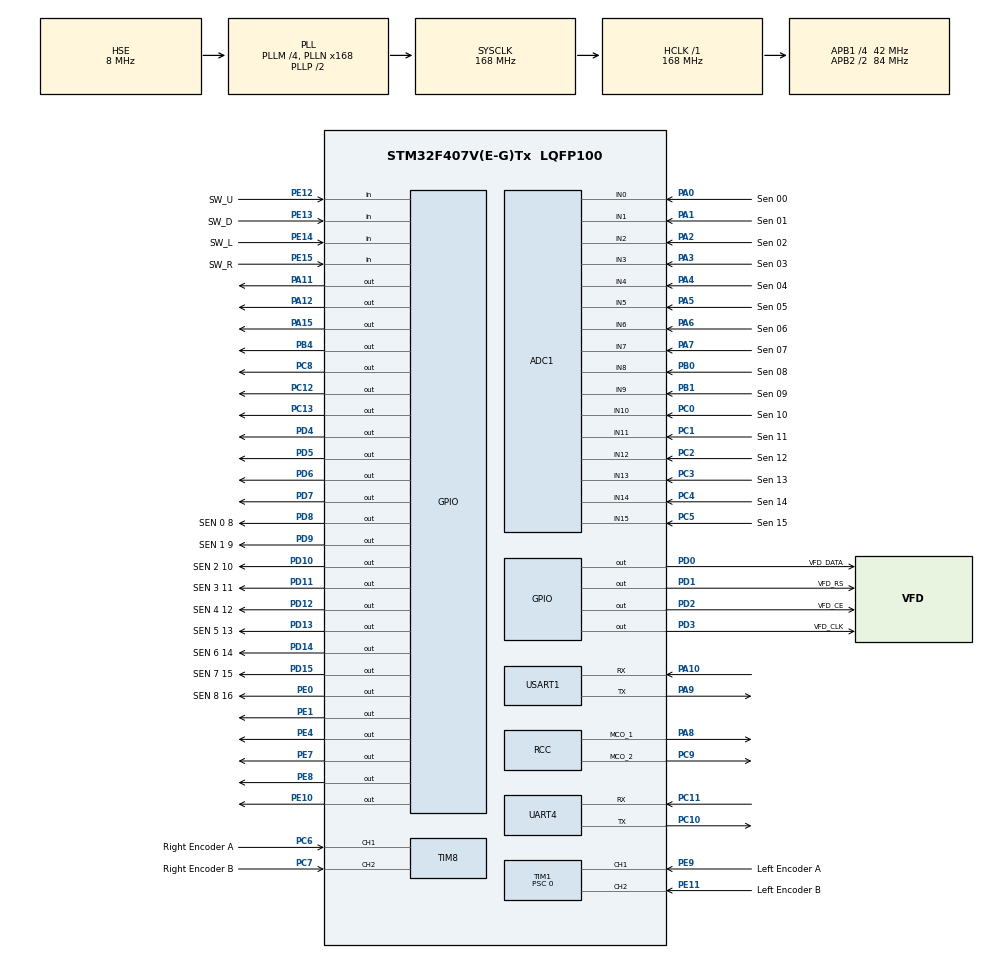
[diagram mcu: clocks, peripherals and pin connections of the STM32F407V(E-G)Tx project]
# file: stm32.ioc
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ADC1.Channel-0\#ChannelRegularConversion=ADC_CHANNEL_9
ADC1.Channel-1\#ChannelRegularConversion=ADC_CHANNEL_0
ADC1.Channel-10\#ChannelRegularConversion=ADC_CHANNEL_0
ADC1.Channel-11\#ChannelRegularConversion=ADC_CHANNEL_0
ADC1.Channel-12\#ChannelRegularConversion=ADC_CHANNEL_0
ADC1.Channel-13\#ChannelRegularConversion=ADC_CHANNEL_0
ADC1.Channel-14\#ChannelRegularConversion=ADC_CHANNEL_0
ADC1.Channel-15\#ChannelRegularConversion=ADC_CHANNEL_0
ADC1.Channel-2\#ChannelRegularConversion=ADC_CHANNEL_0
ADC1.Channel-3\#ChannelRegularConversion=ADC_CHANNEL_0
ADC1.Channel-4\#ChannelRegularConversion=ADC_CHANNEL_0
ADC1.Channel-5\#ChannelRegularConversion=ADC_CHANNEL_0
ADC1.Channel-6\#ChannelRegularConversion=ADC_CHANNEL_0
ADC1.Channel-7\#ChannelRegularConversion=ADC_CHANNEL_0
ADC1.Channel-8\#ChannelRegularConversion=ADC_CHANNEL_0
ADC1.Channel-9\#ChannelRegularConversion=ADC_CHANNEL_0
ADC1.ContinuousConvMode=ENABLE
ADC1.DMAContinuousRequests=ENABLE
ADC1.DiscontinuousConvMode=DISABLE
ADC1.EOCSelection=ADC_EOC_SEQ_CONV
ADC1.NbrOfConversion=16
ADC1.NbrOfConversionFlag=1
ADC1.Rank-0\#ChannelRegularConversion=1
ADC1.Rank-1\#ChannelRegularConversion=2
ADC1.Rank-10\#ChannelRegularConversion=11
ADC1.Rank-11\#ChannelRegularConversion=12
ADC1.Rank-12\#ChannelRegularConversion=13
ADC1.Rank-13\#ChannelRegularConversion=14
ADC1.Rank-14\#ChannelRegularConversion=15
ADC1.Rank-15\#ChannelRegularConversion=16
ADC1.Rank-2\#ChannelRegularConversion=3
ADC1.Rank-3\#ChannelRegularConversion=4
ADC1.Rank-4\#ChannelRegularConversion=5
ADC1.Rank-5\#ChannelRegularConversion=6
ADC1.Rank-6\#ChannelRegularConversion=7
ADC1.Rank-7\#ChannelRegularConversion=8
ADC1.Rank-8\#ChannelRegularConversion=9
ADC1.Rank-9\#ChannelRegularConversion=10
ADC1.SamplingTime-0\#ChannelRegularConversion=ADC_SAMPLETIME_15CYCLES
ADC1.SamplingTime-1\#ChannelRegularConversion=ADC_SAMPLETIME_15CYCLES
ADC1.SamplingTime-10\#ChannelRegularConversion=ADC_SAMPLETIME_15CYCLES
ADC1.SamplingTime-11\#ChannelRegularConversion=ADC_SAMPLETIME_15CYCLES
ADC1.SamplingTime-12\#ChannelRegularConversion=ADC_SAMPLETIME_15CYCLES
ADC1.SamplingTime-13\#ChannelRegularConversion=ADC_SAMPLETIME_15CYCLES
ADC1.SamplingTime-14\#ChannelRegularConversion=ADC_SAMPLETIME_15CYCLES
ADC1.SamplingTime-15\#ChannelRegularConversion=ADC_SAMPLETIME_15CYCLES
ADC1.SamplingTime-2\#ChannelRegularConversion=ADC_SAMPLETIME_15CYCLES
ADC1.SamplingTime-3\#ChannelRegularConversion=ADC_SAMPLETIME_15CYCLES
ADC1.SamplingTime-4\#ChannelRegularConversion=ADC_SAMPLETIME_15CYCLES
ADC1.SamplingTime-5\#ChannelRegularConversion=ADC_SAMPLETIME_15CYCLES
ADC1.SamplingTime-6\#ChannelRegularConversion=ADC_SAMPLETIME_15CYCLES
ADC1.SamplingTime-7\#ChannelRegularConversion=ADC_SAMPLETIME_15CYCLES
ADC1.SamplingTime-8\#ChannelRegularConversion=ADC_SAMPLETIME_15CYCLES
ADC1.SamplingTime-9\#ChannelRegularConversion=ADC_SAMPLETIME_15CYCLES
ADC1.master=1
Dma.ADC1.0.Direction=DMA_PERIPH_TO_MEMORY
Dma.ADC1.0.FIFOMode=DMA_FIFOMODE_DISABLE
Dma.ADC1.0.Instance=DMA2_Stream0
Dma.ADC1.0.MemDataAlignment=DMA_MDATAALIGN_WORD
Dma.ADC1.0.MemInc=DMA_MINC_ENABLE
Dma.ADC1.0.Mode=DMA_CIRCULAR
Dma.ADC1.0.PeriphDataAlignment=DMA_PDATAALIGN_WORD
Dma.ADC1.0.PeriphInc=DMA_PINC_DISABLE
Dma.ADC1.0.Priority=DMA_PRIORITY_LOW
Dma.Request0=ADC1
Mcu.Family=STM32F4
Mcu.Name=STM32F407V(E-G)Tx
Mcu.Package=LQFP100
NVIC.ADC_IRQn=true\:0\:0\:false\:false\:true\:true\:true\:true
NVIC.DMA2_Stream0_IRQn=true\:0\:0\:false\:false\:true\:false\:true\:true
NVIC.PriorityGroup=NVIC_PRIORITYGROUP_4
NVIC.TIM1_BRK_TIM9_IRQn=true\:0\:0\:false\:false\:true\:true\:true\:true
NVIC.TIM4_IRQn=true\:0\:0\:false\:false\:true\:true\:true\:true
PA0-WKUP.GPIO_Label=Sen 00
PA0-WKUP.Signal=ADCx_IN0
PA1.GPIO_Label=Sen 01
PA1.Signal=ADCx_IN1
PA10.Mode=Asynchronous
PA10.Signal=USART1_RX
PA11.Signal=GPIO_Output
PA12.Signal=GPIO_Output
PA13.Mode=Serial_Wire
PA13.Signal=SYS_JTMS-SWDIO
PA14.Mode=Serial_Wire
PA14.Signal=SYS_JTCK-SWCLK
PA15.PinState=GPIO_PIN_SET
PA15.Signal=GPIO_Output
PA2.GPIO_Label=Sen 02
PA2.Signal=ADCx_IN2
PA3.GPIO_Label=Sen 03
PA3.Signal=ADCx_IN3
PA4.GPIO_Label=Sen 04
PA4.Signal=ADCx_IN4
PA5.GPIO_Label=Sen 05
PA5.Signal=ADCx_IN5
PA6.GPIO_Label=Sen 06
PA6.Signal=ADCx_IN6
PA7.GPIO_Label=Sen 07
PA7.Signal=ADCx_IN7
PA8.Mode=Clock-out-1
PA8.Signal=RCC_MCO_1
PA9.Mode=Asynchronous
PA9.Signal=USART1_TX
PB0.GPIO_Label=Sen 08
PB0.Signal=ADCx_IN8
PB1.GPIO_Label=Sen 09
PB1.Signal=ADCx_IN9
PB10.Signal=I2C2_SCL
PB11.Signal=I2C2_SDA
PB12.Signal=SPI2_NSS
PB13.Signal=SPI2_SCK
PB14.Signal=SPI2_MISO
PB15.Signal=SPI2_MOSI
PB3.Signal=SYS_JTDO-SWO
PB4.Signal=GPIO_Output
PB5.GPIO_Label=Right Motor
PB5.Signal=S_TIM3_CH2
PB6.GPIO_Label=Motor Timer A
PB6.Signal=S_TIM4_CH1
PB7.GPIO_Label=Motor Timer B
PB7.Signal=S_TIM4_CH2
PB8.Signal=I2C1_SCL
PB9.Signal=I2C1_SDA
PC0.GPIO_Label=Sen 10
PC0.Signal=ADCx_IN10
PC1.GPIO_Label=Sen 11
PC1.Signal=ADCx_IN11
PC10.Mode=Asynchronous
PC10.Signal=UART4_TX
PC11.Mode=Asynchronous
PC11.Signal=UART4_RX
PC12.Signal=GPIO_Output
PC13-ANTI_TAMP.Signal=GPIO_Output
PC2.GPIO_Label=Sen 12
PC2.Signal=ADCx_IN12
PC3.GPIO_Label=Sen 13
PC3.Signal=ADCx_IN13
PC4.GPIO_Label=Sen 14
PC4.Signal=ADCx_IN14
PC5.GPIO_Label=Sen 15
PC5.Signal=ADCx_IN15
PC6.GPIO_Label=Right Encoder A
PC6.Signal=S_TIM8_CH1
PC7.GPIO_Label=Right Encoder B
PC7.Signal=S_TIM8_CH2
PC8.Signal=GPIO_Output
PC9.Mode=Clock-out-2
PC9.Signal=RCC_MCO_2
PD0.GPIO_Label=VFD_DATA
PD0.Signal=GPIO_Output
PD1.GPIO_Label=VFD_RS
PD1.Signal=GPIO_Output
PD10.GPIO_Label=SEN 2 10
PD10.Signal=GPIO_Output
PD11.GPIO_Label=SEN 3 11
PD11.Signal=GPIO_Output
PD12.GPIO_Label=SEN 4 12
PD12.Signal=GPIO_Output
PD13.GPIO_Label=SEN 5 13
PD13.Signal=GPIO_Output
PD14.GPIO_Label=SEN 6 14
PD14.Signal=GPIO_Output
PD15.GPIO_Label=SEN 7 15
PD15.Signal=GPIO_Output
PD2.GPIO_Label=VFD_CE
PD2.Signal=GPIO_Output
PD3.GPIO_Label=VFD_CLK
PD3.Signal=GPIO_Output
PD4.Signal=GPIO_Output
PD5.Signal=GPIO_Output
PD6.Signal=GPIO_Output
PD7.Signal=GPIO_Output
PD8.GPIO_Label=SEN 0 8
PD8.Signal=GPIO_Output
PD9.GPIO_Label=SEN 1 9
PD9.Signal=GPIO_Output
PE0.GPIO_Label=SEN 8 16
PE0.Signal=GPIO_Output
PE1.Signal=GPIO_Output
PE10.Signal=GPIO_Output
PE11.GPIO_Label=Left Encoder B
PE11.Signal=S_TIM1_CH2
PE12.GPIO_Label=SW_U
PE12.GPIO_PuPd=GPIO_PULLUP
PE12.Signal=GPIO_Input
PE13.GPIO_Label=SW_D
PE13.GPIO_PuPd=GPIO_PULLUP
PE13.Signal=GPIO_Input
PE14.GPIO_Label=SW_L
PE14.GPIO_PuPd=GPIO_PULLUP
PE14.Signal=GPIO_Input
PE15.GPIO_Label=SW_R
PE15.GPIO_PuPd=GPIO_PULLUP
PE15.Signal=GPIO_Input
PE2.Signal=SYS_TRACECLK
PE3.Signal=SYS_TRACED0
PE4.Signal=GPIO_Output
PE5.GPIO_Label=Sensor Timer A
PE5.Signal=S_TIM9_CH1
PE6.GPIO_Label=Sensor Timer B
PE6.Signal=S_TIM9_CH2
PE7.Signal=GPIO_Output
PE8.Signal=GPIO_Output
PE9.GPIO_Label=Left Encoder A
PE9.Signal=S_TIM1_CH1
PH0-OSC_IN.Mode=HSE-External-Oscillator
PH0-OSC_IN.Signal=RCC_OSC_IN
PH1-OSC_OUT.Mode=HSE-External-Oscillator
PH1-OSC_OUT.Signal=RCC_OSC_OUT
ProjectManager.HeapSize=0x200
ProjectManager.StackSize=0x400
ProjectManager.TargetToolchain=Makefile
RCC.48MHZClocksFreq_Value=84000000
RCC.AHBFreq_Value=168000000
RCC.APB1CLKDivider=RCC_HCLK_DIV4
RCC.APB1Freq_Value=42000000
RCC.APB1TimFreq_Value=84000000
RCC.APB2CLKDivider=RCC_HCLK_DIV2
RCC.APB2Freq_Value=84000000
RCC.APB2TimFreq_Value=168000000
RCC.CortexFreq_Value=168000000
RCC.HCLKFreq_Value=168000000
RCC.HSE_VALUE=8000000
RCC.HSI_VALUE=16000000
RCC.LSE_VALUE=32768
RCC.PLLM=4
RCC.PLLN=168
RCC.PLLSourceVirtual=RCC_PLLSOURCE_HSE
RCC.RCC_MCO1Source=RCC_MCO1SOURCE_PLLCLK
RCC.SYSCLKFreq_VALUE=168000000
RCC.SYSCLKSource=RCC_SYSCLKSOURCE_PLLCLK
RCC.VCOOutputFreq_Value=336000000
SH.ADCx_IN0.0=ADC1_IN0,IN0
SH.ADCx_IN1.0=ADC1_IN1,IN1
SH.ADCx_IN10.0=ADC1_IN10,IN10
SH.ADCx_IN11.0=ADC1_IN11,IN11
SH.ADCx_IN12.0=ADC1_IN12,IN12
SH.ADCx_IN13.0=ADC1_IN13,IN13
SH.ADCx_IN14.0=ADC1_IN14,IN14
SH.ADCx_IN15.0=ADC1_IN15,IN15
SH.ADCx_IN2.0=ADC1_IN2,IN2
SH.ADCx_IN3.0=ADC1_IN3,IN3
SH.ADCx_IN4.0=ADC1_IN4,IN4
SH.ADCx_IN5.0=ADC1_IN5,IN5
SH.ADCx_IN6.0=ADC1_IN6,IN6
SH.ADCx_IN7.0=ADC1_IN7,IN7
SH.ADCx_IN8.0=ADC1_IN8,IN8
SH.ADCx_IN9.0=ADC1_IN9,IN9
SH.S_TIM1_CH1.0=TIM1_CH1,Encoder_Interface
SH.S_TIM1_CH2.0=TIM1_CH2,Encoder_Interface
SH.S_TIM3_CH2.0=TIM3_CH2
SH.S_TIM4_CH1.0=TIM4_CH1
SH.S_TIM4_CH2.0=TIM4_CH2
SH.S_TIM8_CH1.0=TIM8_CH1,Encoder_Interface
SH.S_TIM8_CH2.0=TIM8_CH2,Encoder_Interface
SH.S_TIM9_CH1.0=TIM9_CH1
SH.S_TIM9_CH2.0=TIM9_CH2
TIM1.EncoderMode=TIM_ENCODERMODE_TI12
TIM1.IC2Polarity=TIM_ICPOLARITY_RISING
TIM1.Prescaler=0
TIM4.Period=10000 - 1
TIM4.Prescaler=2100 - 1
TIM8.EncoderMode=TIM_ENCODERMODE_TI12
TIM9.Period=84
TIM9.Prescaler=50 - 1
UART4.VirtualMode=Asynchronous
USART1.VirtualMode=VM_ASYNC
VP_TIM4_VS_ClockSourceINT.Mode=Internal
VP_TIM9_VS_ClockSourceINT.Mode=Internal
board=custom

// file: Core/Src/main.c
/* USER CODE BEGIN Header */
/**
  ******************************************************************************
  * @file           : main.c
  * @brief          : Main program body
  ******************************************************************************
  * @attention
  *
  * Copyright (c) 2022 STMicroelectronics.
  * All rights reserved.
  *
  * This software is licensed under terms that can be found in the LICENSE file
  * in the root directory of this software component.
  * If no LICENSE file comes with this software, it is provided AS-IS.
  *
  ******************************************************************************
  */
#define __MAIN__
/* USER CODE END Header */
#include "main.h"

ADC_HandleTypeDef hadc1;
DMA_HandleTypeDef hdma_adc1;

TIM_HandleTypeDef htim1;
TIM_HandleTypeDef htim4;
TIM_HandleTypeDef htim8;
TIM_HandleTypeDef htim9;

UART_HandleTypeDef huart4;
UART_HandleTypeDef huart1;

void SystemClock_Config(void);
static void MX_GPIO_Init(void);
static void MX_DMA_Init(void);
static void MX_ADC1_Init(void);
static void MX_UART4_Init(void);
static void MX_USART1_UART_Init(void);
static void MX_TIM1_Init(void);
static void MX_TIM8_Init(void);
static void MX_TIM4_Init(void);
static void MX_TIM9_Init(void);

int main(void)
{

  /* MCU Configuration--------------------------------------------------------*/

  /* Reset of all peripherals, Initializes the Flash interface and the Systick. */
  HAL_Init();

  /* Configure the system clock */
  SystemClock_Config();

  /* Initialize all configured peripherals */
  MX_GPIO_Init();
  MX_DMA_Init();
  MX_ADC1_Init();
  MX_UART4_Init();
  MX_USART1_UART_Init();
  MX_TIM1_Init();
  MX_TIM8_Init();
  MX_TIM4_Init();
  MX_TIM9_Init();
  /* USER CODE BEGIN 2 */
  PrintMenu();

  HAL_TIM_Base_Start_IT(&htim4);
  g_int32_sen_cnt = 0;
  test = 0;
  int32 i = 0;
  /* USER CODE END 2 */

  /* Infinite loop */
  /* USER CODE BEGIN WHILE */
  while (1)
  {
  	test++;

	//Check 2. 4095가 같은 곳에서 나오는지 확인
    for(int i = 0; i < 16; i++)
	{
		TxPrintf("[%u] ", g_sen[i]);
	}
	printf("\n");
	HAL_Delay(1000);
	//HAL_GPIO_TogglePin(GPIOE, GPIO_PIN_0);
    /* USER CODE END WHILE */

  }
}

void SystemClock_Config(void)
{
  RCC_OscInitTypeDef RCC_OscInitStruct = {0};
  RCC_ClkInitTypeDef RCC_ClkInitStruct = {0};

  /** Configure the main internal regulator output voltage
  */
  __HAL_RCC_PWR_CLK_ENABLE();
  __HAL_PWR_VOLTAGESCALING_CONFIG(PWR_REGULATOR_VOLTAGE_SCALE1);

  /** Initializes the RCC Oscillators according to the specified parameters
  * in the RCC_OscInitTypeDef structure.
  */
  RCC_OscInitStruct.OscillatorType = RCC_OSCILLATORTYPE_HSE;
  RCC_OscInitStruct.HSEState = RCC_HSE_ON;
  RCC_OscInitStruct.PLL.PLLState = RCC_PLL_ON;
  RCC_OscInitStruct.PLL.PLLSource = RCC_PLLSOURCE_HSE;
  RCC_OscInitStruct.PLL.PLLM = 4;
  RCC_OscInitStruct.PLL.PLLN = 168;
  RCC_OscInitStruct.PLL.PLLP = RCC_PLLP_DIV2;
  RCC_OscInitStruct.PLL.PLLQ = 4;
  if (HAL_RCC_OscConfig(&RCC_OscInitStruct) != HAL_OK)
  {
    Error_Handler();
  }

  /** Initializes the CPU, AHB and APB buses clocks
  */
  RCC_ClkInitStruct.ClockType = RCC_CLOCKTYPE_HCLK|RCC_CLOCKTYPE_SYSCLK
                              |RCC_CLOCKTYPE_PCLK1|RCC_CLOCKTYPE_PCLK2;
  RCC_ClkInitStruct.SYSCLKSource = RCC_SYSCLKSOURCE_PLLCLK;
  RCC_ClkInitStruct.AHBCLKDivider = RCC_SYSCLK_DIV1;
  RCC_ClkInitStruct.APB1CLKDivider = RCC_HCLK_DIV4;
  RCC_ClkInitStruct.APB2CLKDivider = RCC_HCLK_DIV2;

  if (HAL_RCC_ClockConfig(&RCC_ClkInitStruct, FLASH_LATENCY_5) != HAL_OK)
  {
    Error_Handler();
  }
  HAL_RCC_MCOConfig(RCC_MCO1, RCC_MCO1SOURCE_PLLCLK, RCC_MCODIV_1);
  HAL_RCC_MCOConfig(RCC_MCO2, RCC_MCO2SOURCE_SYSCLK, RCC_MCODIV_1);
}

static void MX_ADC1_Init(void)
{

  ADC_ChannelConfTypeDef sConfig = {0};

  /** Configure the global features of the ADC (Clock, Resolution, Data Alignment and number of conversion)
  */
  hadc1.Instance = ADC1;
  hadc1.Init.ClockPrescaler = ADC_CLOCK_SYNC_PCLK_DIV4;
  hadc1.Init.Resolution = ADC_RESOLUTION_12B;
  hadc1.Init.ScanConvMode = ENABLE;
  hadc1.Init.ContinuousConvMode = ENABLE;
  hadc1.Init.DiscontinuousConvMode = DISABLE;
  hadc1.Init.ExternalTrigConvEdge = ADC_EXTERNALTRIGCONVEDGE_NONE;
  hadc1.Init.ExternalTrigConv = ADC_SOFTWARE_START;
  hadc1.Init.DataAlign = ADC_DATAALIGN_RIGHT;
  hadc1.Init.NbrOfConversion = 16;
  hadc1.Init.DMAContinuousRequests = ENABLE;
  hadc1.Init.EOCSelection = ADC_EOC_SEQ_CONV;
  if (HAL_ADC_Init(&hadc1) != HAL_OK)
  {
    Error_Handler();
  }

  /** Configure for the selected ADC regular channel its corresponding rank in the sequencer and its sample time.
  */
  sConfig.Channel = ADC_CHANNEL_9;
  sConfig.Rank = 1;
  sConfig.SamplingTime = ADC_SAMPLETIME_15CYCLES;
  if (HAL_ADC_ConfigChannel(&hadc1, &sConfig) != HAL_OK)
  {
    Error_Handler();
  }

  /** Configure for the selected ADC regular channel its corresponding rank in the sequencer and its sample time.
  */
  sConfig.Channel = ADC_CHANNEL_0;
  sConfig.Rank = 2;
  if (HAL_ADC_ConfigChannel(&hadc1, &sConfig) != HAL_OK)
  {
    Error_Handler();
  }

  /** Configure for the selected ADC regular channel its corresponding rank in the sequencer and its sample time.
  */
  sConfig.Rank = 3;
  if (HAL_ADC_ConfigChannel(&hadc1, &sConfig) != HAL_OK)
  {
    Error_Handler();
  }

  /** Configure for the selected ADC regular channel its corresponding rank in the sequencer and its sample time.
  */
  sConfig.Rank = 4;
  if (HAL_ADC_ConfigChannel(&hadc1, &sConfig) != HAL_OK)
  {
    Error_Handler();
  }

  /** Configure for the selected ADC regular channel its corresponding rank in the sequencer and its sample time.
  */
  sConfig.Rank = 5;
  if (HAL_ADC_ConfigChannel(&hadc1, &sConfig) != HAL_OK)
  {
    Error_Handler();
  }

  /** Configure for the selected ADC regular channel its corresponding rank in the sequencer and its sample time.
  */
  sConfig.Rank = 6;
  if (HAL_ADC_ConfigChannel(&hadc1, &sConfig) != HAL_OK)
  {
    Error_Handler();
  }

  /** Configure for the selected ADC regular channel its corresponding rank in the sequencer and its sample time.
  */
  sConfig.Rank = 7;
  if (HAL_ADC_ConfigChannel(&hadc1, &sConfig) != HAL_OK)
  {
    Error_Handler();
  }

  /** Configure for the selected ADC regular channel its corresponding rank in the sequencer and its sample time.
  */
  sConfig.Rank = 8;
  if (HAL_ADC_ConfigChannel(&hadc1, &sConfig) != HAL_OK)
  {
    Error_Handler();
  }

  /** Configure for the selected ADC regular channel its corresponding rank in the sequencer and its sample time.
  */
  sConfig.Rank = 9;
  if (HAL_ADC_ConfigChannel(&hadc1, &sConfig) != HAL_OK)
  {
    Error_Handler();
  }

  /** Configure for the selected ADC regular channel its corresponding rank in the sequencer and its sample time.
  */
  sConfig.Rank = 10;
  if (HAL_ADC_ConfigChannel(&hadc1, &sConfig) != HAL_OK)
  {
    Error_Handler();
  }

  /** Configure for the selected ADC regular channel its corresponding rank in the sequencer and its sample time.
  */
  sConfig.Rank = 11;
  if (HAL_ADC_ConfigChannel(&hadc1, &sConfig) != HAL_OK)
  {
    Error_Handler();
  }

  /** Configure for the selected ADC regular channel its corresponding rank in the sequencer and its sample time.
  */
  sConfig.Rank = 12;
  if (HAL_ADC_ConfigChannel(&hadc1, &sConfig) != HAL_OK)
  {
    Error_Handler();
  }

  /** Configure for the selected ADC regular channel its corresponding rank in the sequencer and its sample time.
  */
  sConfig.Rank = 13;
  if (HAL_ADC_ConfigChannel(&hadc1, &sConfig) != HAL_OK)
  {
    Error_Handler();
  }

  /** Configure for the selected ADC regular channel its corresponding rank in the sequencer and its sample time.
  */
  sConfig.Rank = 14;
  if (HAL_ADC_ConfigChannel(&hadc1, &sConfig) != HAL_OK)
  {
    Error_Handler();
  }

  /** Configure for the selected ADC regular channel its corresponding rank in the sequencer and its sample time.
  */
  sConfig.Rank = 15;
  if (HAL_ADC_ConfigChannel(&hadc1, &sConfig) != HAL_OK)
  {
    Error_Handler();
  }

  /** Configure for the selected ADC regular channel its corresponding rank in the sequencer and its sample time.
  */
  sConfig.Rank = 16;
  if (HAL_ADC_ConfigChannel(&hadc1, &sConfig) != HAL_OK)
  {
    Error_Handler();
  }

}

static void MX_TIM1_Init(void)
{

  TIM_Encoder_InitTypeDef sConfig = {0};
  TIM_MasterConfigTypeDef sMasterConfig = {0};

  htim1.Instance = TIM1;
  htim1.Init.Prescaler = 0;
  htim1.Init.CounterMode = TIM_COUNTERMODE_UP;
  htim1.Init.Period = 65535;
  htim1.Init.ClockDivision = TIM_CLOCKDIVISION_DIV1;
  htim1.Init.RepetitionCounter = 0;
  htim1.Init.AutoReloadPreload = TIM_AUTORELOAD_PRELOAD_DISABLE;
  sConfig.EncoderMode = TIM_ENCODERMODE_TI12;
  sConfig.IC1Polarity = TIM_ICPOLARITY_RISING;
  sConfig.IC1Selection = TIM_ICSELECTION_DIRECTTI;
  sConfig.IC1Prescaler = TIM_ICPSC_DIV1;
  sConfig.IC1Filter = 0;
  sConfig.IC2Polarity = TIM_ICPOLARITY_RISING;
  sConfig.IC2Selection = TIM_ICSELECTION_DIRECTTI;
  sConfig.IC2Prescaler = TIM_ICPSC_DIV1;
  sConfig.IC2Filter = 0;
  if (HAL_TIM_Encoder_Init(&htim1, &sConfig) != HAL_OK)
  {
    Error_Handler();
  }
  sMasterConfig.MasterOutputTrigger = TIM_TRGO_RESET;
  sMasterConfig.MasterSlaveMode = TIM_MASTERSLAVEMODE_DISABLE;
  if (HAL_TIMEx_MasterConfigSynchronization(&htim1, &sMasterConfig) != HAL_OK)
  {
    Error_Handler();
  }

}

static void MX_TIM4_Init(void)
{

  TIM_ClockConfigTypeDef sClockSourceConfig = {0};
  TIM_MasterConfigTypeDef sMasterConfig = {0};

  htim4.Instance = TIM4;
  htim4.Init.Prescaler = 2100 - 1;
  htim4.Init.CounterMode = TIM_COUNTERMODE_UP;
  htim4.Init.Period = 10000 - 1;
  htim4.Init.ClockDivision = TIM_CLOCKDIVISION_DIV1;
  htim4.Init.AutoReloadPreload = TIM_AUTORELOAD_PRELOAD_DISABLE;
  if (HAL_TIM_Base_Init(&htim4) != HAL_OK)
  {
    Error_Handler();
  }
  sClockSourceConfig.ClockSource = TIM_CLOCKSOURCE_INTERNAL;
  if (HAL_TIM_ConfigClockSource(&htim4, &sClockSourceConfig) != HAL_OK)
  {
    Error_Handler();
  }
  sMasterConfig.MasterOutputTrigger = TIM_TRGO_RESET;
  sMasterConfig.MasterSlaveMode = TIM_MASTERSLAVEMODE_DISABLE;
  if (HAL_TIMEx_MasterConfigSynchronization(&htim4, &sMasterConfig) != HAL_OK)
  {
    Error_Handler();
  }

}

static void MX_TIM8_Init(void)
{

  TIM_Encoder_InitTypeDef sConfig = {0};
  TIM_MasterConfigTypeDef sMasterConfig = {0};

  htim8.Instance = TIM8;
  htim8.Init.Prescaler = 0;
  htim8.Init.CounterMode = TIM_COUNTERMODE_UP;
  htim8.Init.Period = 65535;
  htim8.Init.ClockDivision = TIM_CLOCKDIVISION_DIV1;
  htim8.Init.RepetitionCounter = 0;
  htim8.Init.AutoReloadPreload = TIM_AUTORELOAD_PRELOAD_DISABLE;
  sConfig.EncoderMode = TIM_ENCODERMODE_TI12;
  sConfig.IC1Polarity = TIM_ICPOLARITY_RISING;
  sConfig.IC1Selection = TIM_ICSELECTION_DIRECTTI;
  sConfig.IC1Prescaler = TIM_ICPSC_DIV1;
  sConfig.IC1Filter = 0;
  sConfig.IC2Polarity = TIM_ICPOLARITY_RISING;
  sConfig.IC2Selection = TIM_ICSELECTION_DIRECTTI;
  sConfig.IC2Prescaler = TIM_ICPSC_DIV1;
  sConfig.IC2Filter = 0;
  if (HAL_TIM_Encoder_Init(&htim8, &sConfig) != HAL_OK)
  {
    Error_Handler();
  }
  sMasterConfig.MasterOutputTrigger = TIM_TRGO_RESET;
  sMasterConfig.MasterSlaveMode = TIM_MASTERSLAVEMODE_DISABLE;
  if (HAL_TIMEx_MasterConfigSynchronization(&htim8, &sMasterConfig) != HAL_OK)
  {
    Error_Handler();
  }

}

static void MX_TIM9_Init(void)
{

  TIM_ClockConfigTypeDef sClockSourceConfig = {0};

  htim9.Instance = TIM9;
  htim9.Init.Prescaler = 50 - 1;
  htim9.Init.CounterMode = TIM_COUNTERMODE_UP;
  htim9.Init.Period = 84;
  htim9.Init.ClockDivision = TIM_CLOCKDIVISION_DIV1;
  htim9.Init.AutoReloadPreload = TIM_AUTORELOAD_PRELOAD_DISABLE;
  if (HAL_TIM_Base_Init(&htim9) != HAL_OK)
  {
    Error_Handler();
  }
  sClockSourceConfig.ClockSource = TIM_CLOCKSOURCE_INTERNAL;
  if (HAL_TIM_ConfigClockSource(&htim9, &sClockSourceConfig) != HAL_OK)
  {
    Error_Handler();
  }

}

static void MX_UART4_Init(void)
{

  huart4.Instance = UART4;
  huart4.Init.BaudRate = 115200;
  huart4.Init.WordLength = UART_WORDLENGTH_8B;
  huart4.Init.StopBits = UART_STOPBITS_1;
  huart4.Init.Parity = UART_PARITY_NONE;
  huart4.Init.Mode = UART_MODE_TX_RX;
  huart4.Init.HwFlowCtl = UART_HWCONTROL_NONE;
  huart4.Init.OverSampling = UART_OVERSAMPLING_16;
  if (HAL_UART_Init(&huart4) != HAL_OK)
  {
    Error_Handler();
  }

}

static void MX_USART1_UART_Init(void)
{

  huart1.Instance = USART1;
  huart1.Init.BaudRate = 115200;
  huart1.Init.WordLength = UART_WORDLENGTH_8B;
  huart1.Init.StopBits = UART_STOPBITS_1;
  huart1.Init.Parity = UART_PARITY_NONE;
  huart1.Init.Mode = UART_MODE_TX_RX;
  huart1.Init.HwFlowCtl = UART_HWCONTROL_NONE;
  huart1.Init.OverSampling = UART_OVERSAMPLING_16;
  if (HAL_UART_Init(&huart1) != HAL_OK)
  {
    Error_Handler();
  }

}

static void MX_DMA_Init(void)
{

  /* DMA controller clock enable */
  __HAL_RCC_DMA2_CLK_ENABLE();

  /* DMA interrupt init */
  /* DMA2_Stream0_IRQn interrupt configuration */
  HAL_NVIC_SetPriority(DMA2_Stream0_IRQn, 0, 0);
  HAL_NVIC_EnableIRQ(DMA2_Stream0_IRQn);

}

static void MX_GPIO_Init(void)
{
  GPIO_InitTypeDef GPIO_InitStruct = {0};

  /* GPIO Ports Clock Enable */
  __HAL_RCC_GPIOE_CLK_ENABLE();
  __HAL_RCC_GPIOC_CLK_ENABLE();
  __HAL_RCC_GPIOH_CLK_ENABLE();
  __HAL_RCC_GPIOA_CLK_ENABLE();
  __HAL_RCC_GPIOB_CLK_ENABLE();
  __HAL_RCC_GPIOD_CLK_ENABLE();

  /*Configure GPIO pin Output Level */
  HAL_GPIO_WritePin(GPIOE, GPIO_PIN_4|GPIO_PIN_7|GPIO_PIN_8|GPIO_PIN_10
                          |SEN_8_16_Pin|GPIO_PIN_1, GPIO_PIN_RESET);

  /*Configure GPIO pin Output Level */
  HAL_GPIO_WritePin(GPIOC, GPIO_PIN_13|GPIO_PIN_8|GPIO_PIN_12, GPIO_PIN_RESET);

  /*Configure GPIO pin Output Level */
  HAL_GPIO_WritePin(GPIOD, SEN_0_8_Pin|SEN_1_9_Pin|SEN_2_10_Pin|SEN_3_11_Pin
                          |SEN_4_12_Pin|SEN_5_13_Pin|SEN_6_14_Pin|SEN_7_15_Pin
                          |VFD_DATA_Pin|VFD_RS_Pin|VFD_CE_Pin|VFD_CLK_Pin
                          |GPIO_PIN_4|GPIO_PIN_5|GPIO_PIN_6|GPIO_PIN_7, GPIO_PIN_RESET);

  /*Configure GPIO pin Output Level */
  HAL_GPIO_WritePin(GPIOA, GPIO_PIN_11|GPIO_PIN_12, GPIO_PIN_RESET);

  /*Configure GPIO pin Output Level */
  HAL_GPIO_WritePin(GPIOA, GPIO_PIN_15, GPIO_PIN_SET);

  /*Configure GPIO pin Output Level */
  HAL_GPIO_WritePin(GPIOB, GPIO_PIN_4, GPIO_PIN_RESET);

  /*Configure GPIO pins : PE4 PE7 PE8 PE10
                           SEN_8_16_Pin PE1 */
  GPIO_InitStruct.Pin = GPIO_PIN_4|GPIO_PIN_7|GPIO_PIN_8|GPIO_PIN_10
                          |SEN_8_16_Pin|GPIO_PIN_1;
  GPIO_InitStruct.Mode = GPIO_MODE_OUTPUT_PP;
  GPIO_InitStruct.Pull = GPIO_NOPULL;
  GPIO_InitStruct.Speed = GPIO_SPEED_FREQ_LOW;
  HAL_GPIO_Init(GPIOE, &GPIO_InitStruct);

  /*Configure GPIO pins : PC13 PC8 PC12 */
  GPIO_InitStruct.Pin = GPIO_PIN_13|GPIO_PIN_8|GPIO_PIN_12;
  GPIO_InitStruct.Mode = GPIO_MODE_OUTPUT_PP;
  GPIO_InitStruct.Pull = GPIO_NOPULL;
  GPIO_InitStruct.Speed = GPIO_SPEED_FREQ_LOW;
  HAL_GPIO_Init(GPIOC, &GPIO_InitStruct);

  /*Configure GPIO pins : SW_U_Pin SW_D_Pin SW_L_Pin SW_R_Pin */
  GPIO_InitStruct.Pin = SW_U_Pin|SW_D_Pin|SW_L_Pin|SW_R_Pin;
  GPIO_InitStruct.Mode = GPIO_MODE_INPUT;
  GPIO_InitStruct.Pull = GPIO_PULLUP;
  HAL_GPIO_Init(GPIOE, &GPIO_InitStruct);

  /*Configure GPIO pins : PB10 PB11 */
  GPIO_InitStruct.Pin = GPIO_PIN_10|GPIO_PIN_11;
  GPIO_InitStruct.Mode = GPIO_MODE_AF_OD;
  GPIO_InitStruct.Pull = GPIO_NOPULL;
  GPIO_InitStruct.Speed = GPIO_SPEED_FREQ_VERY_HIGH;
  GPIO_InitStruct.Alternate = GPIO_AF4_I2C2;
  HAL_GPIO_Init(GPIOB, &GPIO_InitStruct);

  /*Configure GPIO pins : PB12 PB13 PB14 PB15 */
  GPIO_InitStruct.Pin = GPIO_PIN_12|GPIO_PIN_13|GPIO_PIN_14|GPIO_PIN_15;
  GPIO_InitStruct.Mode = GPIO_MODE_AF_PP;
  GPIO_InitStruct.Pull = GPIO_NOPULL;
  GPIO_InitStruct.Speed = GPIO_SPEED_FREQ_VERY_HIGH;
  GPIO_InitStruct.Alternate = GPIO_AF5_SPI2;
  HAL_GPIO_Init(GPIOB, &GPIO_InitStruct);

  /*Configure GPIO pins : SEN_0_8_Pin SEN_1_9_Pin SEN_2_10_Pin SEN_3_11_Pin
                           SEN_4_12_Pin SEN_5_13_Pin SEN_6_14_Pin SEN_7_15_Pin
                           VFD_DATA_Pin VFD_RS_Pin VFD_CE_Pin VFD_CLK_Pin
                           PD4 PD5 PD6 PD7 */
  GPIO_InitStruct.Pin = SEN_0_8_Pin|SEN_1_9_Pin|SEN_2_10_Pin|SEN_3_11_Pin
                          |SEN_4_12_Pin|SEN_5_13_Pin|SEN_6_14_Pin|SEN_7_15_Pin
                          |VFD_DATA_Pin|VFD_RS_Pin|VFD_CE_Pin|VFD_CLK_Pin
                          |GPIO_PIN_4|GPIO_PIN_5|GPIO_PIN_6|GPIO_PIN_7;
  GPIO_InitStruct.Mode = GPIO_MODE_OUTPUT_PP;
  GPIO_InitStruct.Pull = GPIO_NOPULL;
  GPIO_InitStruct.Speed = GPIO_SPEED_FREQ_LOW;
  HAL_GPIO_Init(GPIOD, &GPIO_InitStruct);

  /*Configure GPIO pin : PC9 */
  GPIO_InitStruct.Pin = GPIO_PIN_9;
  GPIO_InitStruct.Mode = GPIO_MODE_AF_PP;
  GPIO_InitStruct.Pull = GPIO_NOPULL;
  GPIO_InitStruct.Speed = GPIO_SPEED_FREQ_LOW;
  GPIO_InitStruct.Alternate = GPIO_AF0_MCO;
  HAL_GPIO_Init(GPIOC, &GPIO_InitStruct);

  /*Configure GPIO pin : PA8 */
  GPIO_InitStruct.Pin = GPIO_PIN_8;
  GPIO_InitStruct.Mode = GPIO_MODE_AF_PP;
  GPIO_InitStruct.Pull = GPIO_NOPULL;
  GPIO_InitStruct.Speed = GPIO_SPEED_FREQ_LOW;
  GPIO_InitStruct.Alternate = GPIO_AF0_MCO;
  HAL_GPIO_Init(GPIOA, &GPIO_InitStruct);

  /*Configure GPIO pins : PA11 PA12 PA15 */
  GPIO_InitStruct.Pin = GPIO_PIN_11|GPIO_PIN_12|GPIO_PIN_15;
  GPIO_InitStruct.Mode = GPIO_MODE_OUTPUT_PP;
  GPIO_InitStruct.Pull = GPIO_NOPULL;
  GPIO_InitStruct.Speed = GPIO_SPEED_FREQ_LOW;
  HAL_GPIO_Init(GPIOA, &GPIO_InitStruct);

  /*Configure GPIO pin : PB4 */
  GPIO_InitStruct.Pin = GPIO_PIN_4;
  GPIO_InitStruct.Mode = GPIO_MODE_OUTPUT_PP;
  GPIO_InitStruct.Pull = GPIO_NOPULL;
  GPIO_InitStruct.Speed = GPIO_SPEED_FREQ_LOW;
  HAL_GPIO_Init(GPIOB, &GPIO_InitStruct);

  /*Configure GPIO pin : Right_Motor_Pin */
  GPIO_InitStruct.Pin = Right_Motor_Pin;
  GPIO_InitStruct.Mode = GPIO_MODE_AF_PP;
  GPIO_InitStruct.Pull = GPIO_NOPULL;
  GPIO_InitStruct.Speed = GPIO_SPEED_FREQ_LOW;
  GPIO_InitStruct.Alternate = GPIO_AF2_TIM3;
  HAL_GPIO_Init(Right_Motor_GPIO_Port, &GPIO_InitStruct);

  /*Configure GPIO pins : PB8 PB9 */
  GPIO_InitStruct.Pin = GPIO_PIN_8|GPIO_PIN_9;
  GPIO_InitStruct.Mode = GPIO_MODE_AF_OD;
  GPIO_InitStruct.Pull = GPIO_NOPULL;
  GPIO_InitStruct.Speed = GPIO_SPEED_FREQ_VERY_HIGH;
  GPIO_InitStruct.Alternate = GPIO_AF4_I2C1;
  HAL_GPIO_Init(GPIOB, &GPIO_InitStruct);

}

void Error_Handler(void)
{
  __disable_irq();
  while (1)
  {
  }
}
